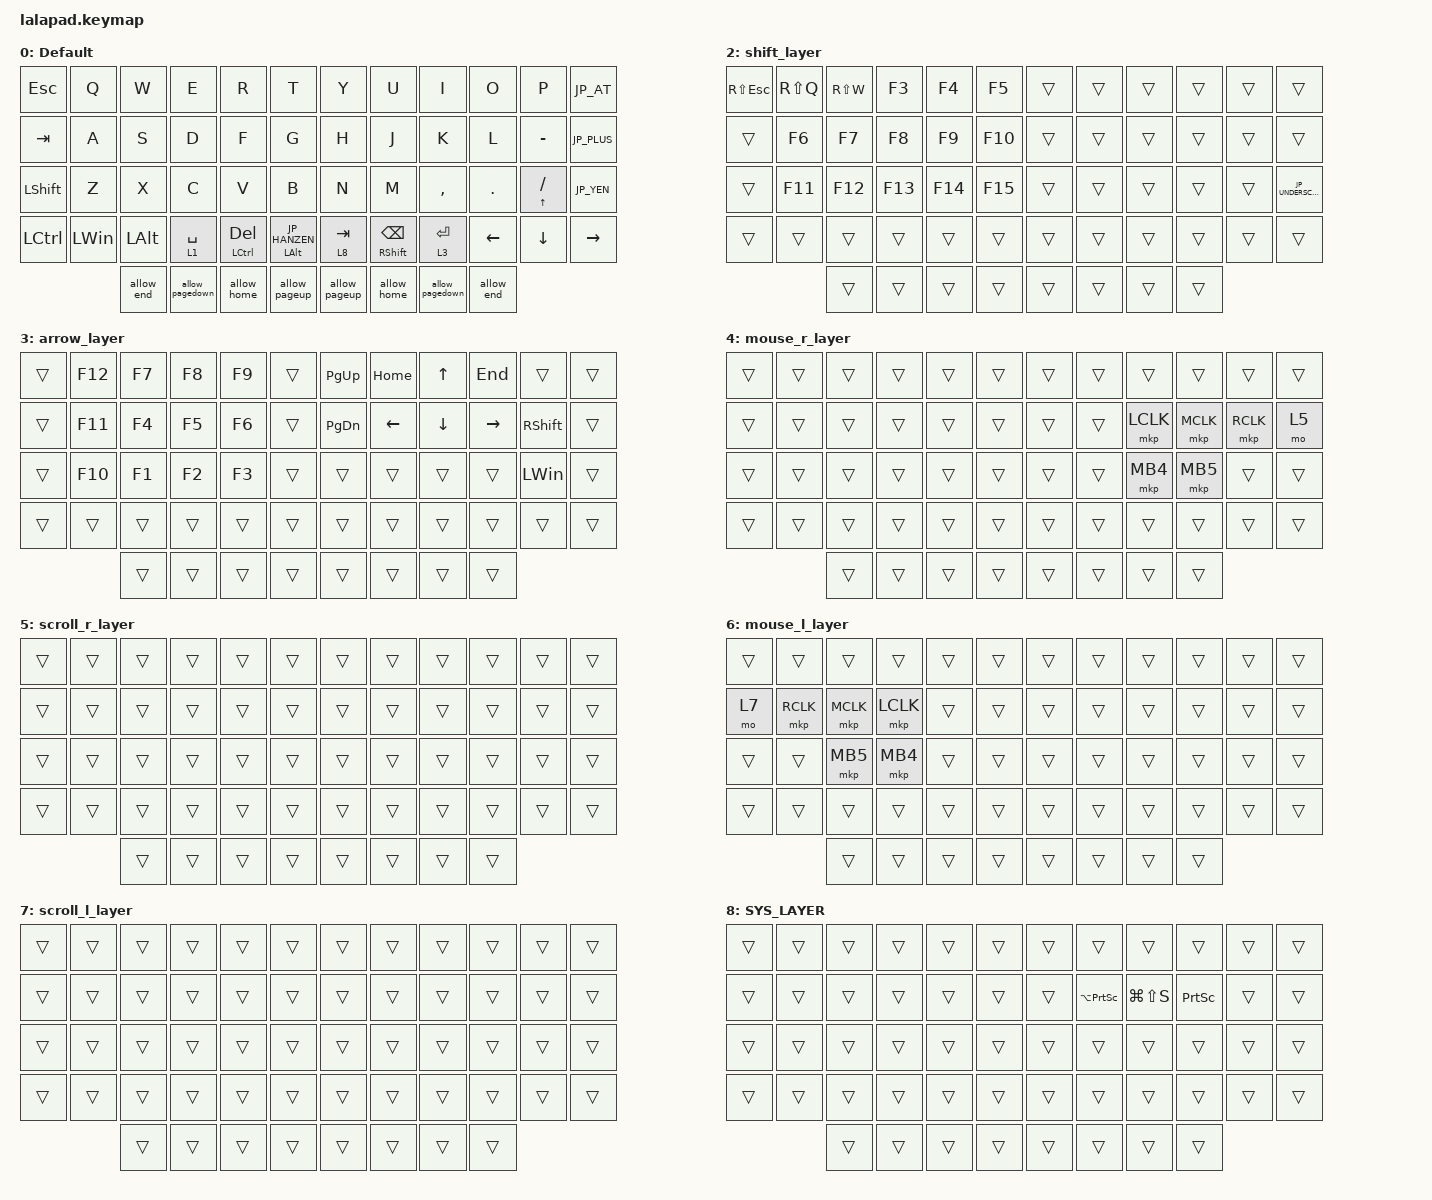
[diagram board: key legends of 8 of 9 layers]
#include <input/processors.dtsi>
#include <behaviors.dtsi>
#include <dt-bindings/zmk/keys.h>
#include <dt-bindings/zmk/pointing.h>

#define DEFAULT_LAYER   0
#define SECONDARY_LAYER 1
#define TERTIARY_LAYER  2
#define SYSTEM_LAYER    3
#define MOUSE_R_LAYER   4
#define SCROLL_R_LAYER  5
#define MOUSE_L_LAYER   6
#define SCROLL_L_LAYER  7

// OS設定を日本語キーボードのまま使用するための変換定義

#define JP_DQUOTE       AT                // "
#define JP_AMPERSAND    CARET             // &
#define JP_QUOTE        AMPERSAND         // '
#define JP_EQUAL        UNDER             // =
#define JP_CARET        EQUAL             // ^
#define JP_YEN          0x89              // ¥
#define JP_PLUS         COLON             // +
#define JP_TILDE        PLUS              // ~
#define JP_PIPE         LS(0x89)          // |
#define JP_AT           LEFT_BRACKET      // @
#define JP_COLON        SINGLE_QUOTE      // :
#define JP_ASTERISK     DOUBLE_QUOTES     // *
#define JP_BACKQUOTE    LEFT_BRACE        // `
#define JP_UNDERSCORE   LS(0x87)          // _
#define JP_LBRACKET     RIGHT_BRACKET     // [
#define JP_RBRACKET     BACKSLASH         // ]
#define JP_LPAREN       ASTERISK          // (
#define JP_RPAREN       LEFT_PARENTHESIS  // )
#define JP_LBRACE       RIGHT_BRACE       // {
#define JP_RBRACE       PIPE              // }
#define JP_KANA         LANGUAGE_1        // かな
#define JP_EISU         LANGUAGE_2        // 英数
#define JP_HANZEN       GRAVE             // 半角/全角

// Mouse Scroll Value

#define ZMK_POINTING_DEFAULT_SCRL_VAL 100

// cirque trackpad input&layer control

&glidepoint_listener_R {
    input-processors =
        <&zip_xy_transform (INPUT_TRANSFORM_XY_SWAP | INPUT_TRANSFORM_X_INVERT | INPUT_TRANSFORM_Y_INVERT)>,
        <&zip_xy_scaler 3 2>,
        <&zip_temp_layer MOUSE_R_LAYER 500>;

    lowspeedmode {
        layers = <SECONDARY_LAYER>;
        input-processors =
            <&zip_xy_transform (INPUT_TRANSFORM_XY_SWAP | INPUT_TRANSFORM_X_INVERT | INPUT_TRANSFORM_Y_INVERT)>,
            <&zip_xy_scaler 3 5>,
            <&zip_temp_layer MOUSE_R_LAYER 500>;
    };

    scroller {
        layers = <SCROLL_R_LAYER>;
        input-processors =
            <&zip_xy_to_scroll_mapper>,
            <&zip_scroll_transform (INPUT_TRANSFORM_XY_SWAP | INPUT_TRANSFORM_Y_INVERT)>,
            <&zip_scroll_scaler 1 8>;
    };
};

&glidepoint_listener_L {
    input-processors =
        <&zip_xy_transform (INPUT_TRANSFORM_XY_SWAP | INPUT_TRANSFORM_X_INVERT | INPUT_TRANSFORM_Y_INVERT)>,
        <&zip_xy_scaler 3 2>,
        <&zip_temp_layer MOUSE_L_LAYER 500>;

    lowspeedmode {
        layers = <SECONDARY_LAYER>;
        input-processors =
            <&zip_xy_transform (INPUT_TRANSFORM_XY_SWAP | INPUT_TRANSFORM_X_INVERT | INPUT_TRANSFORM_Y_INVERT)>,
            <&zip_xy_scaler 3 4>,
            <&zip_temp_layer MOUSE_L_LAYER 500>;
    };

    scroller {
        layers = <SCROLL_L_LAYER>;
        input-processors =
            <&zip_xy_to_scroll_mapper>,
            <&zip_scroll_transform (INPUT_TRANSFORM_XY_SWAP | INPUT_TRANSFORM_Y_INVERT)>,
            <&zip_scroll_scaler 1 6>;
    };
};

/ {
    behaviors {
        // Encoder to Mouse Scroll

        scroll_up_down: sensor_scroll_up_down {
            compatible = "zmk,behavior-sensor-rotate";
            #sensor-binding-cells = <0>;
            bindings = <&msc SCRL_UP>, <&msc SCRL_DOWN>;

            tap-ms = <20>;
            label = "SCROLL_UP_DOWN";
        };

        scroll_down_up: sensor_scroll_down_up {
            compatible = "zmk,behavior-sensor-rotate";
            #sensor-binding-cells = <0>;
            bindings = <&msc SCRL_DOWN>, <&msc SCRL_UP>;

            tap-ms = <20>;
            label = "SCROLL_DOWN_UP";
        };

        scroll_left_right: sensor_scroll_left_right {
            compatible = "zmk,behavior-sensor-rotate";
            #sensor-binding-cells = <0>;
            bindings = <&msc SCRL_LEFT>, <&msc SCRL_RIGHT>;

            tap-ms = <20>;
            label = "SCROLL_LEFT_RIGHT";
        };

        scroll_right_left: sensor_scroll_right_left {
            compatible = "zmk,behavior-sensor-rotate";
            #sensor-binding-cells = <0>;
            bindings = <&msc SCRL_RIGHT>, <&msc SCRL_LEFT>;

            tap-ms = <20>;
            label = "SCROLL_RIGHT_LEFT";
        };

        volume_up_down: sensor_volume_up_down {
            compatible = "zmk,behavior-sensor-rotate";
            #sensor-binding-cells = <0>;
            bindings = <&kp C_VOLUME_UP>, <&kp C_VOLUME_DOWN>;

            tap-ms = <20>;
            label = "VOLUME_UP_DOWN";
        };

        dot_comma: dot_comma {
            compatible = "zmk,behavior-mod-morph";
            #binding-cells = <0>;
            bindings = <&kp KP_DOT>, <&kp COMMA>;

            mods = <(MOD_LSFT|MOD_RSFT)>;
            label = "DOT_COMMA";
        };

        pls_minus: pls_minus {
            compatible = "zmk,behavior-mod-morph";
            #binding-cells = <0>;
            bindings = <&kp PLUS>, <&kp MINUS>;

            mods = <(MOD_LSFT|MOD_RSFT)>;
            label = "PLS_MINUS";
        };

        allow_pageup: allow_pageup {
            compatible = "zmk,behavior-mod-morph";
            #binding-cells = <0>;
            bindings = <&kp UP>, <&kp PAGE_UP>;

            mods = <(MOD_LCTL|MOD_RCTL)>;
            label = "ALLOW_PAGEUP";
        };

        allow_pagedown: allow_pagedown {
            compatible = "zmk,behavior-mod-morph";
            #binding-cells = <0>;
            bindings = <&kp DOWN>, <&kp PAGE_DOWN>;

            mods = <(MOD_LCTL|MOD_RCTL)>;
            label = "ALLOW_PAGEDOWN";
        };

        allow_home: allow_home {
            compatible = "zmk,behavior-mod-morph";
            #binding-cells = <0>;
            bindings = <&kp LEFT>, <&kp HOME>;

            mods = <(MOD_LCTL|MOD_RCTL)>;
            label = "ALLOW_HOME";
        };

        allow_end: allow_end {
            compatible = "zmk,behavior-mod-morph";
            #binding-cells = <0>;
            bindings = <&kp RIGHT>, <&kp END>;

            mods = <(MOD_LCTL|MOD_RCTL)>;
            label = "ALLOW_END";
        };

        mt2: mod_tap2 {
            compatible = "zmk,behavior-hold-tap";
            #binding-cells = <2>;
            flavor = "tap-preferred";
            tapping-term-ms = <200>;
            quick-tap-ms = <200>;
            require-prior-idle-ms = <125>;
            bindings = <&kp>, <&kp>;
        };
    };

    keymap {
        compatible = "zmk,keymap";

        DEFAULT_LAYER {
            display-name = "Default";
            sensor-bindings = <&scroll_down_up>, <&scroll_up_down>;

            bindings = <
&kp ESC    &kp Q         &kp W         &kp E            &kp R                     &kp T                    &kp Y          &kp U                       &kp I            &kp O       &kp P                &kp JP_AT
&kp TAB    &kp A         &kp S         &kp D            &kp F                     &kp G                    &kp H          &kp J                       &kp K            &kp L       &kp MINUS            &kp JP_PLUS
&kp LSHFT  &kp Z         &kp X         &kp C            &kp V                     &kp B                    &kp N          &kp M                       &kp COMMA        &kp PERIOD  &mt2 UP_ARROW SLASH  &kp JP_YEN
&kp LCTRL  &kp LEFT_WIN  &kp LEFT_ALT  &lt 1 SPACE      &mt2 LEFT_CONTROL DELETE  &mt2 LEFT_ALT JP_HANZEN  &lt 8 TAB      &mt2 RIGHT_SHIFT BACKSPACE  &lt 3 ENTER      &kp LEFT    &kp DOWN             &kp RIGHT
                         &allow_end    &allow_pagedown  &allow_home               &allow_pageup            &allow_pageup  &allow_home                 &allow_pagedown  &allow_end
            >;
        };

        NUM_SYM_LAYER {
            display-name = "num_sym_layer";
            sensor-bindings = <&scroll_left_right>, <&scroll_left_right>;

            bindings = <
&kp JP_TILDE      &kp MINUS     &kp NUMBER_7  &kp NUMBER_8  &kp NUMBER_9                &kp JP_PLUS      &kp JP_QUOTE   &kp JP_LBRACKET  &kp JP_RBRACKET  &kp RS(NUMBER_5)  &trans  &trans
&kp JP_CARET      &kp SLASH     &kp NUMBER_4  &kp NUMBER_5  &mt2 LEFT_CONTROL NUMBER_6  &kp JP_ASTERISK  &kp JP_DQUOTE  &kp JP_LPAREN    &kp JP_RPAREN    &kp JP_AMPERSAND  &trans  &trans
&kp RS(NUMBER_1)  &kp NUMBER_0  &kp NUMBER_1  &kp NUMBER_2  &kp NUMBER_3                &kp JP_EQUAL     &kp SEMICOLON  &kp JP_LBRACE    &kp JP_RBRACE    &kp JP_PIPE       &trans  &trans
&trans            &trans        &trans        &trans        &trans                      &trans           &kp JP_COLON   &trans           &trans           &trans            &trans  &trans
                                &trans        &trans        &trans                      &trans           &trans         &trans           &trans
            >;
        };

        SHIFT_LAYER {
            display-name = "shift_layer";
            bindings = <
&kp RS(ESC)  &kp RS(Q)  &kp RS(W)  &kp F3   &kp F4   &kp F5   &trans  &trans  &trans  &trans  &trans  &trans
&trans       &kp F6     &kp F7     &kp F8   &kp F9   &kp F10  &trans  &trans  &trans  &trans  &trans  &trans
&trans       &kp F11    &kp F12    &kp F13  &kp F14  &kp F15  &trans  &trans  &trans  &trans  &trans  &kp JP_UNDERSCORE
&trans       &trans     &trans     &trans   &trans   &trans   &trans  &trans  &trans  &trans  &trans  &trans
                        &trans     &trans   &trans   &trans   &trans  &trans  &trans  &trans
            >;
        };

        ARROW_LAYER {
            display-name = "arrow_layer";
            sensor-bindings = <&scroll_down_up>, <&volume_up_down>;

            bindings = <
&trans  &kp F12  &kp F7  &kp F8  &kp F9  &trans  &kp PAGE_UP    &kp HOME        &kp UP_ARROW    &kp END          &trans           &trans
&trans  &kp F11  &kp F4  &kp F5  &kp F6  &trans  &kp PAGE_DOWN  &kp LEFT_ARROW  &kp DOWN_ARROW  &kp RIGHT_ARROW  &kp RIGHT_SHIFT  &trans
&trans  &kp F10  &kp F1  &kp F2  &kp F3  &trans  &trans         &trans          &trans          &trans           &kp LEFT_WIN     &trans
&trans  &trans   &trans  &trans  &trans  &trans  &trans         &trans          &trans          &trans           &trans           &trans
                 &trans  &trans  &trans  &trans  &trans         &trans          &trans          &trans
            >;
        };

        MOUSE_R_LAYER {
            display-name = "mouse_r_layer";
            bindings = <
&trans  &trans  &trans  &trans  &trans  &trans  &trans  &trans  &trans     &trans     &trans     &trans
&trans  &trans  &trans  &trans  &trans  &trans  &trans  &trans  &mkp LCLK  &mkp MCLK  &mkp RCLK  &mo 5
&trans  &trans  &trans  &trans  &trans  &trans  &trans  &trans  &mkp MB4   &mkp MB5   &trans     &trans
&trans  &trans  &trans  &trans  &trans  &trans  &trans  &trans  &trans     &trans     &trans     &trans
                &trans  &trans  &trans  &trans  &trans  &trans  &trans     &trans
            >;
        };

        SCROLL_R_LAYER {
            display-name = "scroll_r_layer";
            bindings = <
&trans  &trans  &trans  &trans  &trans  &trans  &trans  &trans  &trans  &trans  &trans  &trans
&trans  &trans  &trans  &trans  &trans  &trans  &trans  &trans  &trans  &trans  &trans  &trans
&trans  &trans  &trans  &trans  &trans  &trans  &trans  &trans  &trans  &trans  &trans  &trans
&trans  &trans  &trans  &trans  &trans  &trans  &trans  &trans  &trans  &trans  &trans  &trans
                &trans  &trans  &trans  &trans  &trans  &trans  &trans  &trans
            >;
        };

        MOUSE_L_LAYER {
            display-name = "mouse_l_layer";
            bindings = <
&trans  &trans     &trans     &trans     &trans  &trans  &trans  &trans  &trans  &trans  &trans  &trans
&mo 7   &mkp RCLK  &mkp MCLK  &mkp LCLK  &trans  &trans  &trans  &trans  &trans  &trans  &trans  &trans
&trans  &trans     &mkp MB5   &mkp MB4   &trans  &trans  &trans  &trans  &trans  &trans  &trans  &trans
&trans  &trans     &trans     &trans     &trans  &trans  &trans  &trans  &trans  &trans  &trans  &trans
                   &trans     &trans     &trans  &trans  &trans  &trans  &trans  &trans
            >;
        };

        SCROLL_L_LAYER {
            display-name = "scroll_l_layer";
            bindings = <
&trans  &trans  &trans  &trans  &trans  &trans  &trans  &trans  &trans  &trans  &trans  &trans
&trans  &trans  &trans  &trans  &trans  &trans  &trans  &trans  &trans  &trans  &trans  &trans
&trans  &trans  &trans  &trans  &trans  &trans  &trans  &trans  &trans  &trans  &trans  &trans
&trans  &trans  &trans  &trans  &trans  &trans  &trans  &trans  &trans  &trans  &trans  &trans
                &trans  &trans  &trans  &trans  &trans  &trans  &trans  &trans
            >;
        };

        SYS_LAYER {
            bindings = <
&trans  &trans  &trans  &trans  &trans  &trans  &trans  &trans               &trans         &trans           &trans  &trans
&trans  &trans  &trans  &trans  &trans  &trans  &trans  &kp LA(PRINTSCREEN)  &kp LG(LS(S))  &kp PRINTSCREEN  &trans  &trans
&trans  &trans  &trans  &trans  &trans  &trans  &trans  &trans               &trans         &trans           &trans  &trans
&trans  &trans  &trans  &trans  &trans  &trans  &trans  &trans               &trans         &trans           &trans  &trans
                &trans  &trans  &trans  &trans  &trans  &trans               &trans         &trans
            >;
        };
    };
};
